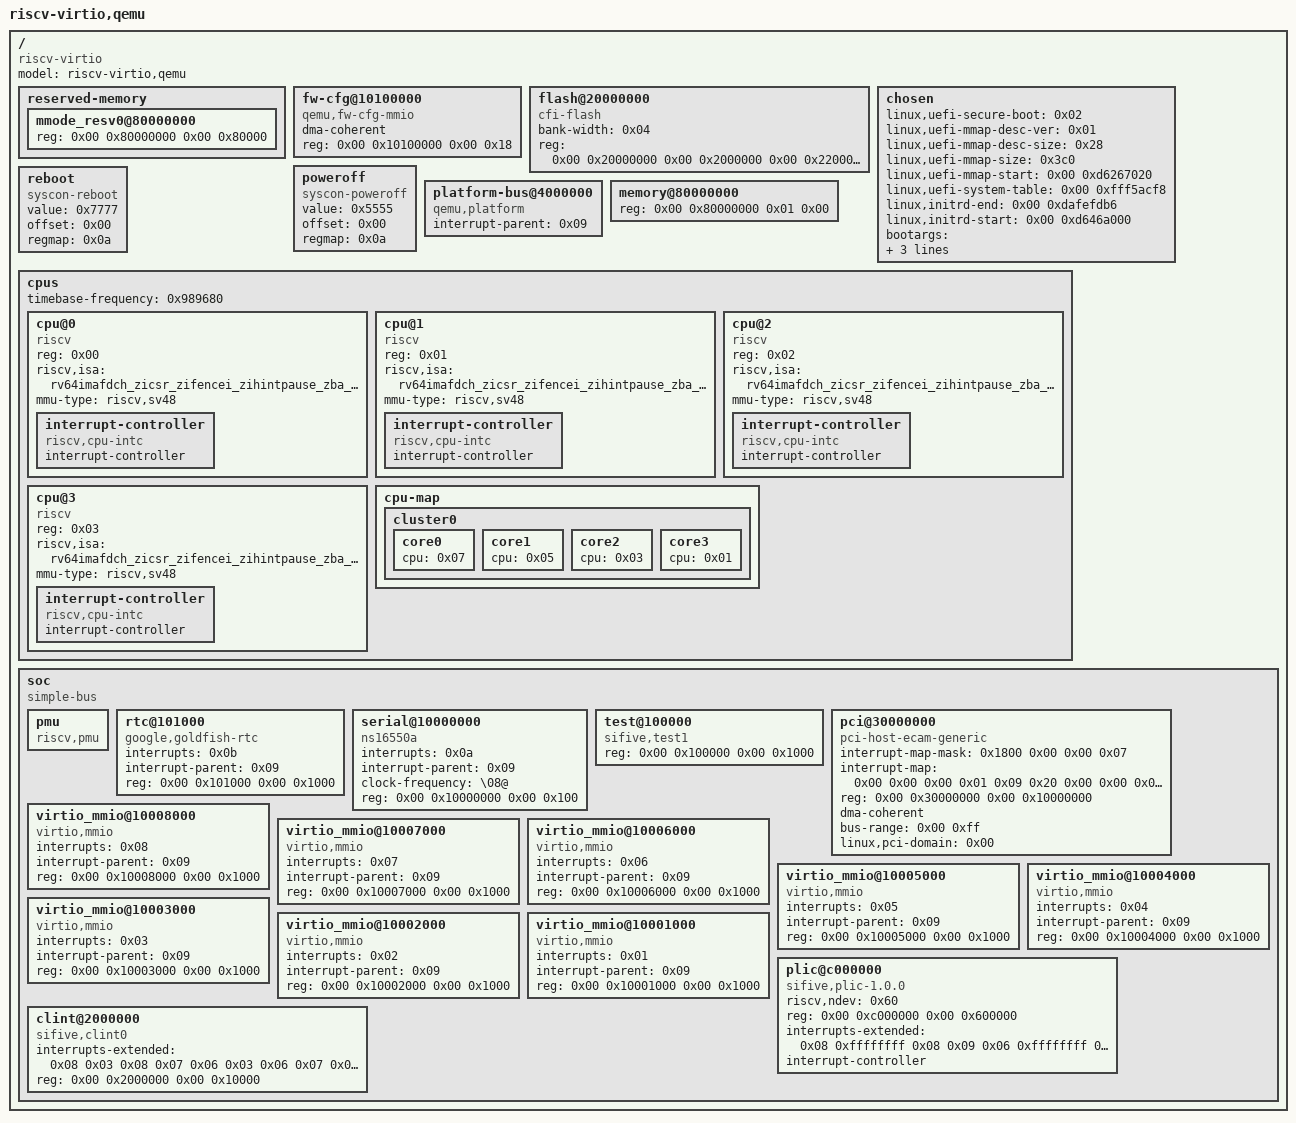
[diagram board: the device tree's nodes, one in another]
/dts-v1/;

/ {
    #address-cells = <0x02>;
    #size-cells = <0x02>;
    compatible = "riscv-virtio";
    model = "riscv-virtio,qemu";

    reserved-memory {
        #address-cells = <0x02>;
        #size-cells = <0x02>;
        ranges;

        mmode_resv0@80000000 {
            reg = <0x00 0x80000000 0x00 0x80000>;
        };
    };

    fw-cfg@10100000 {
        dma-coherent;
        reg = <0x00 0x10100000 0x00 0x18>;
        compatible = "qemu,fw-cfg-mmio";
    };

    flash@20000000 {
        bank-width = <0x04>;
        reg = <0x00 0x20000000 0x00 0x2000000 0x00 0x22000000 0x00 0x2000000>;
        compatible = "cfi-flash";
    };

    chosen {
        linux,uefi-secure-boot = <0x02>;
        linux,uefi-mmap-desc-ver = <0x01>;
        linux,uefi-mmap-desc-size = <0x28>;
        linux,uefi-mmap-size = <0x3c0>;
        linux,uefi-mmap-start = <0x00 0xd6267020>;
        linux,uefi-system-table = <0x00 0xfff5acf8>;
        linux,initrd-end = <0x00 0xdafefdb6>;
        linux,initrd-start = <0x00 0xd646a000>;
        bootargs = "BOOT_IMAGE=/vmlinuz-5.19.0-1012-generic root=/dev/mapper/ubuntu--vg-ubuntu--lv ro";
        boot-hartid = <0x02>;
        stdout-path = "/soc/serial@10000000";
    };

    poweroff {
        value = <0x5555>;
        offset = <0x00>;
        regmap = <0x0a>;
        compatible = "syscon-poweroff";
    };

    reboot {
        value = <0x7777>;
        offset = <0x00>;
        regmap = <0x0a>;
        compatible = "syscon-reboot";
    };

    platform-bus@4000000 {
        interrupt-parent = <0x09>;
        ranges = <0x00 0x00 0x4000000 0x2000000>;
        #address-cells = <0x01>;
        #size-cells = <0x01>;
        compatible = "qemu,platform\0simple-bus";
    };

    memory@80000000 {
        device_type = "memory";
        reg = <0x00 0x80000000 0x01 0x00>;
    };

    cpus {
        #address-cells = <0x01>;
        #size-cells = <0x00>;
        timebase-frequency = <0x989680>;

        cpu@0 {
            phandle = <0x07>;
            device_type = "cpu";
            reg = <0x00>;
            status = "okay";
            compatible = "riscv";
            riscv,isa = "rv64imafdch_zicsr_zifencei_zihintpause_zba_zbb_zbc_zbs_sstc";
            mmu-type = "riscv,sv48";

            interrupt-controller {
                #interrupt-cells = <0x01>;
                interrupt-controller;
                compatible = "riscv,cpu-intc";
                phandle = <0x08>;
            };
        };

        cpu@1 {
            phandle = <0x05>;
            device_type = "cpu";
            reg = <0x01>;
            status = "okay";
            compatible = "riscv";
            riscv,isa = "rv64imafdch_zicsr_zifencei_zihintpause_zba_zbb_zbc_zbs_sstc";
            mmu-type = "riscv,sv48";

            interrupt-controller {
                #interrupt-cells = <0x01>;
                interrupt-controller;
                compatible = "riscv,cpu-intc";
                phandle = <0x06>;
            };
        };

        cpu@2 {
            phandle = <0x03>;
            device_type = "cpu";
            reg = <0x02>;
            status = "okay";
            compatible = "riscv";
            riscv,isa = "rv64imafdch_zicsr_zifencei_zihintpause_zba_zbb_zbc_zbs_sstc";
            mmu-type = "riscv,sv48";

            interrupt-controller {
                #interrupt-cells = <0x01>;
                interrupt-controller;
                compatible = "riscv,cpu-intc";
                phandle = <0x04>;
            };
        };

        cpu@3 {
            phandle = <0x01>;
            device_type = "cpu";
            reg = <0x03>;
            status = "okay";
            compatible = "riscv";
            riscv,isa = "rv64imafdch_zicsr_zifencei_zihintpause_zba_zbb_zbc_zbs_sstc";
            mmu-type = "riscv,sv48";

            interrupt-controller {
                #interrupt-cells = <0x01>;
                interrupt-controller;
                compatible = "riscv,cpu-intc";
                phandle = <0x02>;
            };
        };

        cpu-map {

            cluster0 {

                core0 {
                    cpu = <0x07>;
                };

                core1 {
                    cpu = <0x05>;
                };

                core2 {
                    cpu = <0x03>;
                };

                core3 {
                    cpu = <0x01>;
                };
            };
        };
    };

    soc {
        #address-cells = <0x02>;
        #size-cells = <0x02>;
        compatible = "simple-bus";
        ranges;

        pmu {
            compatible = "riscv,pmu";
        };

        rtc@101000 {
            interrupts = <0x0b>;
            interrupt-parent = <0x09>;
            reg = <0x00 0x101000 0x00 0x1000>;
            compatible = "google,goldfish-rtc";
        };

        serial@10000000 {
            interrupts = <0x0a>;
            interrupt-parent = <0x09>;
            clock-frequency = "\08@";
            reg = <0x00 0x10000000 0x00 0x100>;
            compatible = "ns16550a";
        };

        test@100000 {
            phandle = <0x0a>;
            reg = <0x00 0x100000 0x00 0x1000>;
            compatible = "sifive,test1\0sifive,test0\0syscon";
        };

        pci@30000000 {
            interrupt-map-mask = <0x1800 0x00 0x00 0x07>;
            interrupt-map = <0x00 0x00 0x00 0x01 0x09 0x20 0x00 0x00 0x00 0x02 0x09 0x21 0x00 0x00 0x00 0x03 0x09 0x22 0x00 0x00 0x00 0x04 0x09 0x23 0x800 0x00 0x00 0x01 0x09 0x21 0x800 0x00 0x00 0x02 0x09 0x22 0x800 0x00 0x00 0x03 0x09 0x23 0x800 0x00 0x00 0x04 0x09 0x20 0x1000 0x00 0x00 0x01 0x09 0x22 0x1000 0x00 0x00 0x02 0x09 0x23 0x1000 0x00 0x00 0x03 0x09 0x20 0x1000 0x00 0x00 0x04 0x09 0x21 0x1800 0x00 0x00 0x01 0x09 0x23 0x1800 0x00 0x00 0x02 0x09 0x20 0x1800 0x00 0x00 0x03 0x09 0x21 0x1800 0x00 0x00 0x04 0x09 0x22>;
            ranges = <0x1000000 0x00 0x00 0x00 0x3000000 0x00 0x10000 0x2000000 0x00 0x40000000 0x00 0x40000000 0x00 0x40000000 0x3000000 0x04 0x00 0x04 0x00 0x04 0x00>;
            reg = <0x00 0x30000000 0x00 0x10000000>;
            dma-coherent;
            bus-range = <0x00 0xff>;
            linux,pci-domain = <0x00>;
            device_type = "pci";
            compatible = "pci-host-ecam-generic";
            #size-cells = <0x02>;
            #interrupt-cells = <0x01>;
            #address-cells = <0x03>;
        };

        virtio_mmio@10008000 {
            interrupts = <0x08>;
            interrupt-parent = <0x09>;
            reg = <0x00 0x10008000 0x00 0x1000>;
            compatible = "virtio,mmio";
        };

        virtio_mmio@10007000 {
            interrupts = <0x07>;
            interrupt-parent = <0x09>;
            reg = <0x00 0x10007000 0x00 0x1000>;
            compatible = "virtio,mmio";
        };

        virtio_mmio@10006000 {
            interrupts = <0x06>;
            interrupt-parent = <0x09>;
            reg = <0x00 0x10006000 0x00 0x1000>;
            compatible = "virtio,mmio";
        };

        virtio_mmio@10005000 {
            interrupts = <0x05>;
            interrupt-parent = <0x09>;
            reg = <0x00 0x10005000 0x00 0x1000>;
            compatible = "virtio,mmio";
        };

        virtio_mmio@10004000 {
            interrupts = <0x04>;
            interrupt-parent = <0x09>;
            reg = <0x00 0x10004000 0x00 0x1000>;
            compatible = "virtio,mmio";
        };

        virtio_mmio@10003000 {
            interrupts = <0x03>;
            interrupt-parent = <0x09>;
            reg = <0x00 0x10003000 0x00 0x1000>;
            compatible = "virtio,mmio";
        };

        virtio_mmio@10002000 {
            interrupts = <0x02>;
            interrupt-parent = <0x09>;
            reg = <0x00 0x10002000 0x00 0x1000>;
            compatible = "virtio,mmio";
        };

        virtio_mmio@10001000 {
            interrupts = <0x01>;
            interrupt-parent = <0x09>;
            reg = <0x00 0x10001000 0x00 0x1000>;
            compatible = "virtio,mmio";
        };

        plic@c000000 {
            phandle = <0x09>;
            riscv,ndev = <0x60>;
            reg = <0x00 0xc000000 0x00 0x600000>;
            interrupts-extended = <0x08 0xffffffff 0x08 0x09 0x06 0xffffffff 0x06 0x09 0x04 0xffffffff 0x04 0x09 0x02 0xffffffff 0x02 0x09>;
            interrupt-controller;
            compatible = "sifive,plic-1.0.0\0riscv,plic0";
            #address-cells = <0x00>;
            #interrupt-cells = <0x01>;
        };

        clint@2000000 {
            interrupts-extended = <0x08 0x03 0x08 0x07 0x06 0x03 0x06 0x07 0x04 0x03 0x04 0x07 0x02 0x03 0x02 0x07>;
            reg = <0x00 0x2000000 0x00 0x10000>;
            compatible = "sifive,clint0\0riscv,clint0";
        };
    };
};
